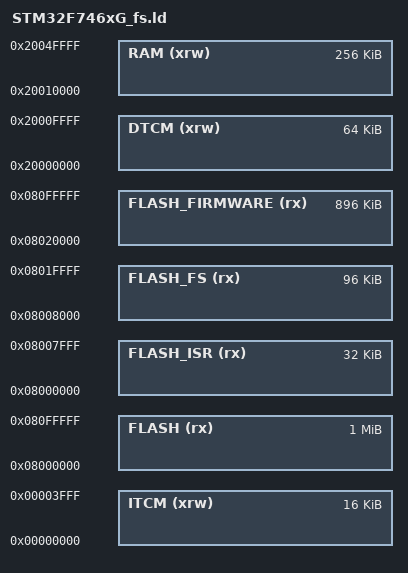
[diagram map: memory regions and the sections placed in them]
/*
 * This file is part of the MicroPython project, http://micropython.org/
 *
 * GNU linker script for STM32F746 with filesystem
 *
 * The MIT License (MIT)
 *
 * Copyright (c) 2020 Mark Olsson <mark@markolsson.se>
 *
 * Permission is hereby granted, free of charge, to any person obtaining a copy
 * of this software and associated documentation files (the "Software"), to deal
 * in the Software without restriction, including without limitation the rights
 * to use, copy, modify, merge, publish, distribute, sublicense, and/or sell
 * copies of the Software, and to permit persons to whom the Software is
 * furnished to do so, subject to the following conditions:
 *
 * The above copyright notice and this permission notice shall be included in
 * all copies or substantial portions of the Software.
 *
 * THE SOFTWARE IS PROVIDED "AS IS", WITHOUT WARRANTY OF ANY KIND, EXPRESS OR
 * IMPLIED, INCLUDING BUT NOT LIMITED TO THE WARRANTIES OF MERCHANTABILITY,
 * FITNESS FOR A PARTICULAR PURPOSE AND NONINFRINGEMENT. IN NO EVENT SHALL THE
 * AUTHORS OR COPYRIGHT HOLDERS BE LIABLE FOR ANY CLAIM, DAMAGES OR OTHER
 * LIABILITY, WHETHER IN AN ACTION OF CONTRACT, TORT OR OTHERWISE, ARISING FROM,
 * OUT OF OR IN CONNECTION WITH THE SOFTWARE OR THE USE OR OTHER DEALINGS IN
 * THE SOFTWARE.
 */

 /* Entry Point */
ENTRY(Reset_Handler)

_ld_default_stack_size = 24K;

/* Specify the memory areas */
MEMORY
{
    FLASH (rx)          : ORIGIN = 0x08000000, LENGTH = 1024K /* entire flash */
    FLASH_ISR (rx)      : ORIGIN = 0x08000000, LENGTH = 32K /* sector 0 */
    FLASH_FS (rx)       : ORIGIN = 0x08008000, LENGTH = 96K /* sectors 1,2,3 are 32K */
    FLASH_FIRMWARE (rx) : ORIGIN = 0x08020000, LENGTH = 896K /* sector 4 is 128K, sectors 5,6,7 are 256K */
    DTCM (xrw)          : ORIGIN = 0x20000000, LENGTH = 64K
    RAM (xrw)           : ORIGIN = 0x20010000, LENGTH = 256K    /* AXI SRAM */
    ITCM (xrw)          : ORIGIN = 0x00000000, LENGTH = 16K
}

/* produce a link error if there is not this amount of RAM for these sections */
_minimum_stack_size = 24K;
_minimum_heap_size = 16K;

/* Define tho top end of the stack.  The stack is full descending so begins just
   above last byte of RAM.  Note that EABI requires the stack to be 8-byte
   aligned for a call. */
_estack = ORIGIN(DTCM) + LENGTH(DTCM);

/* RAM extents for the garbage collector */
_ram_start = ORIGIN(RAM);
_ram_end = ORIGIN(RAM) + LENGTH(RAM);
